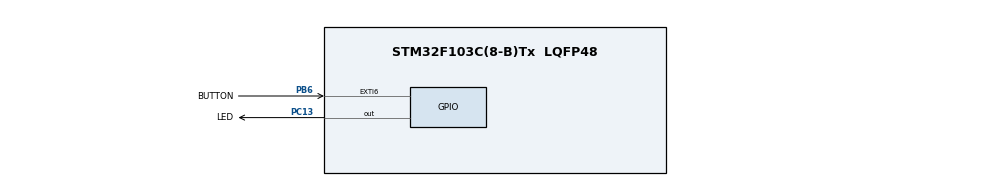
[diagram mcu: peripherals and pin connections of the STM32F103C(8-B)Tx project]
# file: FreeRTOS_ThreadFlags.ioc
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FREERTOS.Tasks01=Task01,24,256,StartTask01,Default,NULL,Dynamic,NULL,NULL;Task02,24,256,StartTask02,Default,NULL,Dynamic,NULL,NULL;Task03,24,256,StartTask03,Default,NULL,Dynamic,NULL,NULL
FREERTOS.configTOTAL_HEAP_SIZE=4000
Mcu.Family=STM32F1
Mcu.Name=STM32F103C(8-B)Tx
Mcu.Package=LQFP48
NVIC.EXTI9_5_IRQn=true\:5\:0\:false\:false\:true\:true\:true\:true\:true
NVIC.PriorityGroup=NVIC_PRIORITYGROUP_4
NVIC.TIM1_UP_IRQn=true\:15\:0\:false\:false\:true\:false\:false\:true\:true
NVIC.TimeBase=TIM1_UP_IRQn
NVIC.TimeBaseIP=TIM1
PA13.Mode=Trace_Asynchronous_SW
PA13.Signal=SYS_JTMS-SWDIO
PA14.Mode=Trace_Asynchronous_SW
PA14.Signal=SYS_JTCK-SWCLK
PB3.Mode=Trace_Asynchronous_SW
PB3.Signal=SYS_JTDO-TRACESWO
PB6.GPIO_Label=BUTTON
PB6.GPIO_ModeDefaultEXTI=GPIO_MODE_IT_FALLING
PB6.GPIO_PuPd=GPIO_PULLUP
PB6.Signal=GPXTI6
PC13-TAMPER-RTC.GPIO_Label=LED
PC13-TAMPER-RTC.Signal=GPIO_Output
PD0-OSC_IN.Mode=HSE-External-Oscillator
PD0-OSC_IN.Signal=RCC_OSC_IN
PD1-OSC_OUT.Mode=HSE-External-Oscillator
PD1-OSC_OUT.Signal=RCC_OSC_OUT
ProjectManager.HeapSize=0x200
ProjectManager.StackSize=0x400
ProjectManager.TargetToolchain=STM32CubeIDE
RCC.APB1Freq_Value=8000000
RCC.APB2Freq_Value=8000000
VP_FREERTOS_VS_CMSIS_V2.Mode=CMSIS_V2
VP_SYS_VS_tim1.Mode=TIM1
board=custom

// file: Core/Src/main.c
/* USER CODE BEGIN Header */
/**
  ******************************************************************************
  * @file           : main.c
  * @brief          : Main program body
  ******************************************************************************
  * @attention
  *
  * Copyright (c) 2024 STMicroelectronics.
  * All rights reserved.
  *
  * This software is licensed under terms that can be found in the LICENSE file
  * in the root directory of this software component.
  * If no LICENSE file comes with this software, it is provided AS-IS.
  *
  ******************************************************************************
  */
/* USER CODE END Header */
#include "main.h"
#include "cmsis_os.h"

/* Definitions for Task01 */
osThreadId_t Task01Handle;
const osThreadAttr_t Task01_attributes = {
  .name = "Task01",
  .stack_size = 256 * 4,
  .priority = (osPriority_t) osPriorityNormal,
};
/* Definitions for Task02 */
osThreadId_t Task02Handle;
const osThreadAttr_t Task02_attributes = {
  .name = "Task02",
  .stack_size = 256 * 4,
  .priority = (osPriority_t) osPriorityNormal,
};
/* Definitions for Task03 */
osThreadId_t Task03Handle;
const osThreadAttr_t Task03_attributes = {
  .name = "Task03",
  .stack_size = 256 * 4,
  .priority = (osPriority_t) osPriorityNormal,
};

void SystemClock_Config(void);
static void MX_GPIO_Init(void);
void StartTask01(void *argument);
void StartTask02(void *argument);
void StartTask03(void *argument);

/* USER CODE BEGIN PFP */
void TaskAction(uint8_t message);
void HAL_GPIO_EXTI_Callback(uint16_t GPIO_Pin);
/* USER CODE END PFP */

int main(void)
{

  /* MCU Configuration--------------------------------------------------------*/

  /* Reset of all peripherals, Initializes the Flash interface and the Systick. */
  HAL_Init();

  /* Configure the system clock */
  SystemClock_Config();

  /* Initialize all configured peripherals */
  MX_GPIO_Init();

  /* Init scheduler */
  osKernelInitialize();

  /* Create the thread(s) */
  /* creation of Task01 */
  Task01Handle = osThreadNew(StartTask01, NULL, &Task01_attributes);

  /* creation of Task02 */
  Task02Handle = osThreadNew(StartTask02, NULL, &Task02_attributes);

  /* creation of Task03 */
  Task03Handle = osThreadNew(StartTask03, NULL, &Task03_attributes);

  /* Start scheduler */
  osKernelStart();

  /* We should never get here as control is now taken by the scheduler */
  /* Infinite loop */
  while (1)
  {

  }
}

void SystemClock_Config(void)
{
  RCC_OscInitTypeDef RCC_OscInitStruct = {0};
  RCC_ClkInitTypeDef RCC_ClkInitStruct = {0};

  /** Initializes the RCC Oscillators according to the specified parameters
  * in the RCC_OscInitTypeDef structure.
  */
  RCC_OscInitStruct.OscillatorType = RCC_OSCILLATORTYPE_HSI;
  RCC_OscInitStruct.HSIState = RCC_HSI_ON;
  RCC_OscInitStruct.HSICalibrationValue = RCC_HSICALIBRATION_DEFAULT;
  RCC_OscInitStruct.PLL.PLLState = RCC_PLL_NONE;
  if (HAL_RCC_OscConfig(&RCC_OscInitStruct) != HAL_OK)
  {
    Error_Handler();
  }

  /** Initializes the CPU, AHB and APB buses clocks
  */
  RCC_ClkInitStruct.ClockType = RCC_CLOCKTYPE_HCLK|RCC_CLOCKTYPE_SYSCLK
                              |RCC_CLOCKTYPE_PCLK1|RCC_CLOCKTYPE_PCLK2;
  RCC_ClkInitStruct.SYSCLKSource = RCC_SYSCLKSOURCE_HSI;
  RCC_ClkInitStruct.AHBCLKDivider = RCC_SYSCLK_DIV1;
  RCC_ClkInitStruct.APB1CLKDivider = RCC_HCLK_DIV1;
  RCC_ClkInitStruct.APB2CLKDivider = RCC_HCLK_DIV1;

  if (HAL_RCC_ClockConfig(&RCC_ClkInitStruct, FLASH_LATENCY_0) != HAL_OK)
  {
    Error_Handler();
  }
}

static void MX_GPIO_Init(void)
{
  GPIO_InitTypeDef GPIO_InitStruct = {0};

  /* GPIO Ports Clock Enable */
  __HAL_RCC_GPIOC_CLK_ENABLE();
  __HAL_RCC_GPIOD_CLK_ENABLE();
  __HAL_RCC_GPIOA_CLK_ENABLE();
  __HAL_RCC_GPIOB_CLK_ENABLE();

  /*Configure GPIO pin Output Level */
  HAL_GPIO_WritePin(LED_GPIO_Port, LED_Pin, GPIO_PIN_RESET);

  /*Configure GPIO pin : LED_Pin */
  GPIO_InitStruct.Pin = LED_Pin;
  GPIO_InitStruct.Mode = GPIO_MODE_OUTPUT_PP;
  GPIO_InitStruct.Pull = GPIO_NOPULL;
  GPIO_InitStruct.Speed = GPIO_SPEED_FREQ_LOW;
  HAL_GPIO_Init(LED_GPIO_Port, &GPIO_InitStruct);

  /*Configure GPIO pin : BUTTON_Pin */
  GPIO_InitStruct.Pin = BUTTON_Pin;
  GPIO_InitStruct.Mode = GPIO_MODE_IT_FALLING;
  GPIO_InitStruct.Pull = GPIO_PULLUP;
  HAL_GPIO_Init(BUTTON_GPIO_Port, &GPIO_InitStruct);

  /* EXTI interrupt init*/
  HAL_NVIC_SetPriority(EXTI9_5_IRQn, 5, 0);
  HAL_NVIC_EnableIRQ(EXTI9_5_IRQn);

}

/* USER CODE BEGIN 4 */
void TaskAction(uint8_t message) {
	ITM_SendChar(message);
	ITM_SendChar('\n');
}

void HAL_GPIO_EXTI_Callback(uint16_t GPIO_Pin) {
	if(GPIO_Pin == BUTTON_Pin) {
		osThreadFlagsSet(Task01Handle, 0x01);
		TaskAction('!');
	}
}
/* USER CODE END 4 */

void StartTask01(void *argument)
{
  /* USER CODE BEGIN 5 */
  /* Infinite loop */
  for(;;)
  {
	osThreadFlagsWait(0x51, osFlagsWaitAll, osWaitForever);
	HAL_GPIO_TogglePin(LED_GPIO_Port, LED_Pin);''
  }
  /* USER CODE END 5 */
}

void StartTask02(void *argument)
{
  /* USER CODE BEGIN StartTask02 */
  /* Infinite loop */
  for(;;)
  {
	osThreadFlagsSet(Task01Handle, 0x50);
	TaskAction('2');
    osDelay(1000);
  }
  /* USER CODE END StartTask02 */
}

void StartTask03(void *argument)
{
  /* USER CODE BEGIN StartTask03 */
  /* Infinite loop */
  for(;;)
  {
    osDelay(1000);
  }
  /* USER CODE END StartTask03 */
}

void HAL_TIM_PeriodElapsedCallback(TIM_HandleTypeDef *htim)
{
  if (htim->Instance == TIM1) {
    HAL_IncTick();
  }
}

void Error_Handler(void)
{
  __disable_irq();
  while (1)
  {
  }
}
